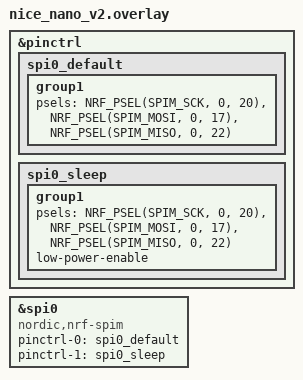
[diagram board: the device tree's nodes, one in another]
&pinctrl {                                            /* spi0 device, default state */
    spi0_default: spi0_default {                      /* can be arbitrary */

        group1 {           
            psels = <NRF_PSEL(SPIM_SCK, 0, 20)>,      /* P0.20 as clock, P0.17 as MOSI, P0.22 as MISO/CS */
                    <NRF_PSEL(SPIM_MOSI, 0, 17)>,
                    <NRF_PSEL(SPIM_MISO, 0, 22)>;
        };
    };

    spi0_sleep: spi0_sleep {                          /* spi0 device, sleep state */
        group1 {           
            psels = <NRF_PSEL(SPIM_SCK, 0, 20)>,      /* P0.20 as clock, P0.17 as MOSI, P0.22 as MISO/CS */
                    <NRF_PSEL(SPIM_MOSI, 0, 17)>,
                    <NRF_PSEL(SPIM_MISO, 0, 22)>;
            low-power-enable;
        };
    };
};

&spi0 {
    compatible = "nordic,nrf-spim";
    pinctrl-0 = <&spi0_default>;
    pinctrl-1 = <&spi0_sleep>;
    pinctrl-names = "default", "sleep";
};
